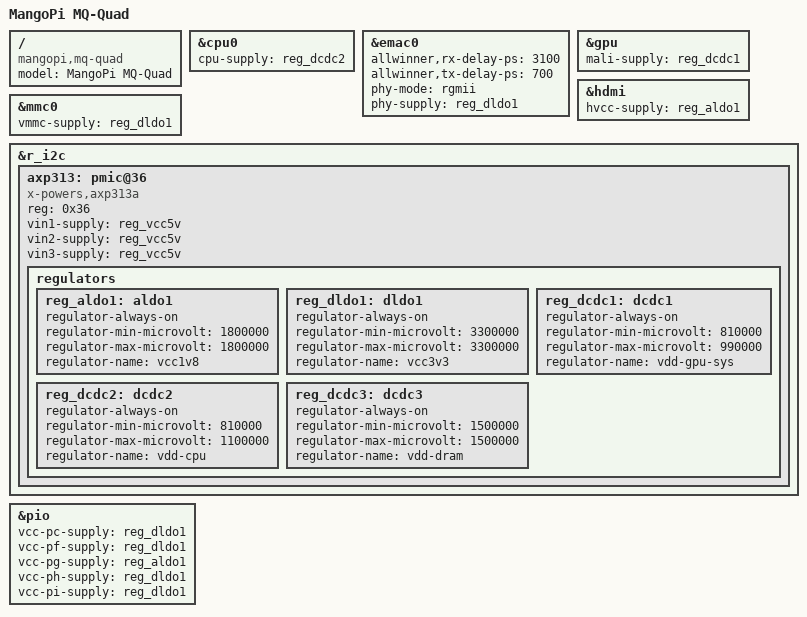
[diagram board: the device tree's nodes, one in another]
// SPDX-License-Identifier: (GPL-2.0+ OR MIT)
/*
 * Copyright (C) 2020 Arm Ltd.
 */

/dts-v1/;

#include "allwinner/sun50i-h616-orangepi-zero.dtsi"

/ {
	model = "MangoPi MQ-Quad";
	compatible = "mangopi,mq-quad", "allwinner,sun50i-h616";
};

&cpu0  {
	cpu-supply = <&reg_dcdc2>;
	status = "okay";
};

&emac0 {
	allwinner,rx-delay-ps = <3100>;
	allwinner,tx-delay-ps = <700>;
	phy-mode = "rgmii";
	phy-supply = <&reg_dldo1>;
};

&gpu {
	mali-supply = <&reg_dcdc1>;
	status = "okay";
};

&hdmi {
	hvcc-supply = <&reg_aldo1>;
};

&mmc0 {
	vmmc-supply = <&reg_dldo1>;
};

&r_i2c {
	status = "okay";

	axp313: pmic@36 {
		compatible = "x-powers,axp313a";
		reg = <0x36>;

		vin1-supply = <&reg_vcc5v>;
		vin2-supply = <&reg_vcc5v>;
		vin3-supply = <&reg_vcc5v>;

		regulators {
			/* Supplies VCC-PLL, so needs to be always on. */
			reg_aldo1: aldo1 {
				regulator-always-on;
				regulator-min-microvolt = <1800000>;
				regulator-max-microvolt = <1800000>;
				regulator-name = "vcc1v8";
			};

			/* Supplies VCC-IO, so needs to be always on. */
			reg_dldo1: dldo1 {
				regulator-always-on;
				regulator-min-microvolt = <3300000>;
				regulator-max-microvolt = <3300000>;
				regulator-name = "vcc3v3";
			};

			reg_dcdc1: dcdc1 {
				regulator-always-on;
				regulator-min-microvolt = <810000>;
				regulator-max-microvolt = <990000>;
				regulator-name = "vdd-gpu-sys";
			};

			reg_dcdc2: dcdc2 {
				regulator-always-on;
				regulator-min-microvolt = <810000>;
				regulator-max-microvolt = <1100000>;
				regulator-name = "vdd-cpu";
			};

			reg_dcdc3: dcdc3 {
				regulator-always-on;
				regulator-min-microvolt = <1500000>;
				regulator-max-microvolt = <1500000>;
				regulator-name = "vdd-dram";
			};
		};
	};
};

&pio {
	vcc-pc-supply = <&reg_dldo1>;
	vcc-pf-supply = <&reg_dldo1>;
	vcc-pg-supply = <&reg_aldo1>;
	vcc-ph-supply = <&reg_dldo1>;
	vcc-pi-supply = <&reg_dldo1>;
};
